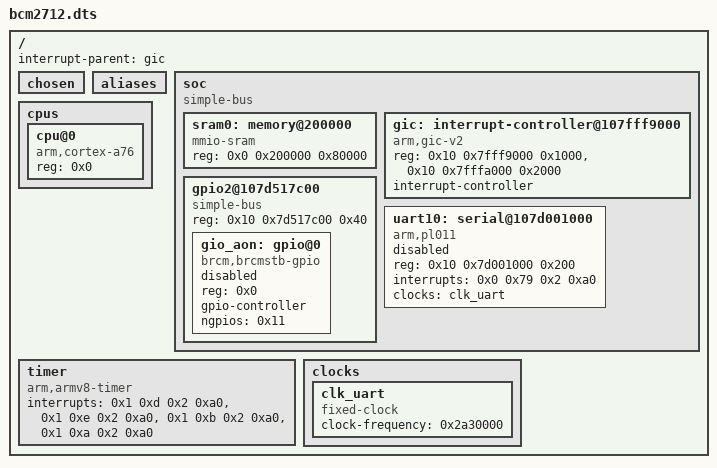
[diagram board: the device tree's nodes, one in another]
/dts-v1/;

/ {
	#address-cells = < 0x1 >;
	#size-cells = < 0x1 >;
	interrupt-parent = < &gic >;
	chosen {
	};
	aliases {
	};
	soc {
		#address-cells = < 0x2 >;
		#size-cells = < 0x1 >;
		compatible = "simple-bus";
		ranges;
		sram0: memory@200000 {
			device_type = "memory";
			compatible = "mmio-sram";
			reg = < 0x0 0x200000 0x80000 >;
		};
		gic: interrupt-controller@107fff9000 {
			compatible = "arm,gic-v2", "arm,gic";
			reg = < 0x10 0x7fff9000 0x1000 >, < 0x10 0x7fffa000 0x2000 >;
			interrupt-controller;
			#interrupt-cells = < 0x4 >;
			status = "okay";
			phandle = < 0x1 >;
		};
		gpio2@107d517c00 {
			compatible = "simple-bus";
			reg = < 0x10 0x7d517c00 0x40 >;
			#address-cells = < 0x1 >;
			#size-cells = < 0x0 >;
			gio_aon: gpio@0 {
				compatible = "brcm,brcmstb-gpio";
				reg = < 0x0 >;
				gpio-controller;
				#gpio-cells = < 0x2 >;
				ngpios = < 0x11 >;
				status = "disabled";
			};
		};
		uart10: serial@107d001000 {
			compatible = "arm,pl011";
			reg = < 0x10 0x7d001000 0x200 >;
			interrupts = < 0x0 0x79 0x2 0xa0 >;
			clocks = < &clk_uart >;
			status = "disabled";
		};
	};
	cpus {
		#address-cells = < 0x1 >;
		#size-cells = < 0x0 >;
		cpu@0 {
			device_type = "cpu";
			compatible = "arm,cortex-a76";
			reg = < 0x0 >;
		};
	};
	timer {
		compatible = "arm,armv8-timer";
		interrupts = < 0x1 0xd 0x2 0xa0 >, < 0x1 0xe 0x2 0xa0 >, < 0x1 0xb 0x2 0xa0 >, < 0x1 0xa 0x2 0xa0 >;
	};
	clocks {
		clk_uart: clk_uart {
			compatible = "fixed-clock";
			clock-frequency = < 0x2a30000 >;
			#clock-cells = < 0x0 >;
			phandle = < 0x2 >;
		};
	};
};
